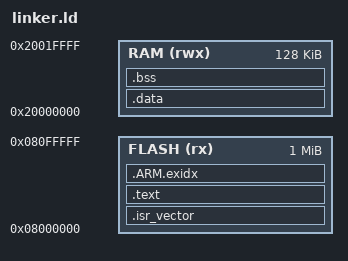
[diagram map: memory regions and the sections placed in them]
ENTRY(Reset_Handler)

MEMORY
{
    FLASH (rx)  : ORIGIN = 0x08000000, LENGTH = 1024K
    RAM   (rwx) : ORIGIN = 0x20000000, LENGTH = 128K
}

_stack_top = ORIGIN(RAM) + LENGTH(RAM);

SECTIONS
{
    .isr_vector :
    {
        . = ALIGN(4);
        KEEP(*(.isr_vector))
        . = ALIGN(4);
    } > FLASH

    .text :
    {
        . = ALIGN(4);
        *(.text*)
        *(.rodata*)
        *(.glue_7)
        *(.glue_7t)
        *(.eh_frame*)
        . = ALIGN(4);
    } > FLASH

    .ARM.exidx :
    {
        *(.ARM.exidx*)
        . = ALIGN(4);
    } > FLASH

    _etext = .;

    .data : AT(_etext)
    {
        . = ALIGN(4);
        _sdata = .;
        *(.data*)
        . = ALIGN(4);
        _edata = .;
    } > RAM

    _sidata = LOADADDR(.data);

    .bss (NOLOAD) :
    {
        . = ALIGN(4);
        _sbss = .;
        *(.bss*)
        *(COMMON)
        . = ALIGN(4);
        _ebss = .;
    } > RAM

    . = ALIGN(8);
    _end = .;
}
